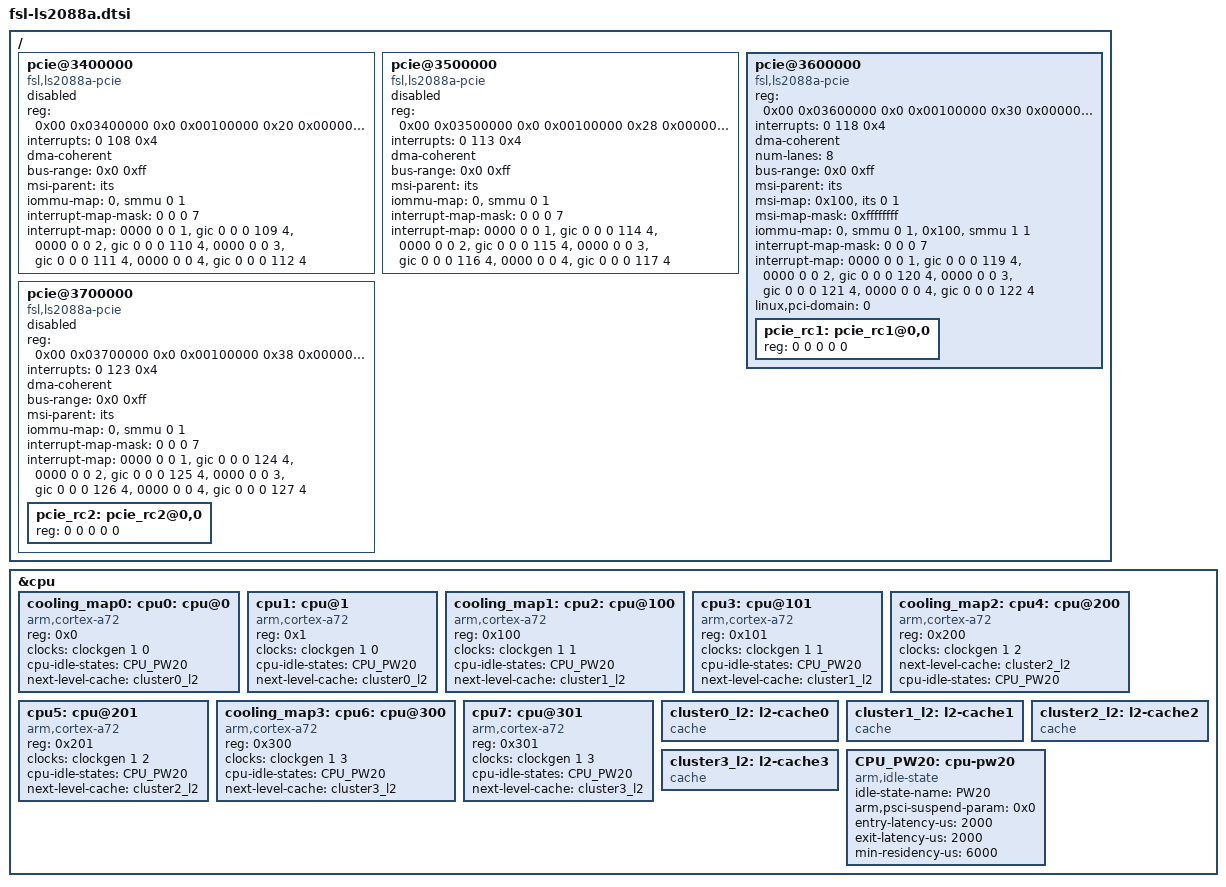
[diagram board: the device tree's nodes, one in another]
// SPDX-License-Identifier: (GPL-2.0+ OR MIT)
/*
 * Device Tree Include file for Freescale Layerscape-2088A family SoC.
 *
 * Copyright 2016 Freescale Semiconductor, Inc.
 * Copyright 2017-2018 NXP
 *
 * Abhimanyu Saini <abhimanyu.saini@nxp.com>
 *
 */

#include "fsl-ls208xa.dtsi"

&cpu {
	cooling_map0: cpu0: cpu@0 {
		device_type = "cpu";
		compatible = "arm,cortex-a72";
		reg = <0x0>;
		clocks = <&clockgen 1 0>;
		cpu-idle-states = <&CPU_PW20>;
		next-level-cache = <&cluster0_l2>;
		#cooling-cells = <2>;
	};

	cpu1: cpu@1 {
		device_type = "cpu";
		compatible = "arm,cortex-a72";
		reg = <0x1>;
		clocks = <&clockgen 1 0>;
		cpu-idle-states = <&CPU_PW20>;
		next-level-cache = <&cluster0_l2>;
		#cooling-cells = <2>;
	};

	cooling_map1: cpu2: cpu@100 {
		device_type = "cpu";
		compatible = "arm,cortex-a72";
		reg = <0x100>;
		clocks = <&clockgen 1 1>;
		cpu-idle-states = <&CPU_PW20>;
		next-level-cache = <&cluster1_l2>;
		#cooling-cells = <2>;
	};

	cpu3: cpu@101 {
		device_type = "cpu";
		compatible = "arm,cortex-a72";
		reg = <0x101>;
		clocks = <&clockgen 1 1>;
		cpu-idle-states = <&CPU_PW20>;
		next-level-cache = <&cluster1_l2>;
		#cooling-cells = <2>;
	};

	cooling_map2: cpu4: cpu@200 {
		device_type = "cpu";
		compatible = "arm,cortex-a72";
		reg = <0x200>;
		clocks = <&clockgen 1 2>;
		next-level-cache = <&cluster2_l2>;
		cpu-idle-states = <&CPU_PW20>;
		#cooling-cells = <2>;
	};

	cpu5: cpu@201 {
		device_type = "cpu";
		compatible = "arm,cortex-a72";
		reg = <0x201>;
		clocks = <&clockgen 1 2>;
		cpu-idle-states = <&CPU_PW20>;
		next-level-cache = <&cluster2_l2>;
		#cooling-cells = <2>;
	};

	cooling_map3: cpu6: cpu@300 {
		device_type = "cpu";
		compatible = "arm,cortex-a72";
		reg = <0x300>;
		clocks = <&clockgen 1 3>;
		cpu-idle-states = <&CPU_PW20>;
		next-level-cache = <&cluster3_l2>;
		#cooling-cells = <2>;
	};

	cpu7: cpu@301 {
		device_type = "cpu";
		compatible = "arm,cortex-a72";
		reg = <0x301>;
		clocks = <&clockgen 1 3>;
		cpu-idle-states = <&CPU_PW20>;
		next-level-cache = <&cluster3_l2>;
		#cooling-cells = <2>;
	};

	cluster0_l2: l2-cache0 {
		compatible = "cache";
	};

	cluster1_l2: l2-cache1 {
		compatible = "cache";
	};

	cluster2_l2: l2-cache2 {
		compatible = "cache";
	};

	cluster3_l2: l2-cache3 {
		compatible = "cache";
	};

	CPU_PW20: cpu-pw20 {
		compatible = "arm,idle-state";
		idle-state-name = "PW20";
		arm,psci-suspend-param = <0x0>;
		entry-latency-us = <2000>;
		exit-latency-us = <2000>;
		min-residency-us = <6000>;
	};
};

/ {
	pcie@3400000 {
		compatible = "fsl,ls2088a-pcie", "snps,dw-pcie";
		reg = <0x00 0x03400000 0x0 0x00100000   /* controller registers */
			0x20 0x00000000 0x0 0x00002000>; /* configuration space */

		ranges = <0x81000000 0x0 0x00000000 0x20 0x00010000 0x0 0x00010000
			0x82000000 0x0 0x40000000 0x20 0x40000000 0x0 0x40000000>;
		reg-names = "regs", "config";
		interrupts = <0 108 0x4>; /* aer interrupt */
		interrupt-names = "aer";
		#address-cells = <3>;
		#size-cells = <2>;
		device_type = "pci";
		dma-coherent;
		bus-range = <0x0 0xff>;
		msi-parent = <&its>;
		iommu-map = <0 &smmu 0 1>;	/* This is fixed-up by u-boot */
		#interrupt-cells = <1>;
		interrupt-map-mask = <0 0 0 7>;
		interrupt-map = <0000 0 0 1 &gic 0 0 0 109 4>,
				<0000 0 0 2 &gic 0 0 0 110 4>,
				<0000 0 0 3 &gic 0 0 0 111 4>,
				<0000 0 0 4 &gic 0 0 0 112 4>;
		status = "disabled";
	};

	pcie@3500000 {
		compatible = "fsl,ls2088a-pcie", "snps,dw-pcie";
		reg = <0x00 0x03500000 0x0 0x00100000   /* controller registers */
			0x28 0x00000000 0x0 0x00002000>; /* configuration space */

		ranges = <0x81000000 0x0 0x00000000 0x28 0x00010000 0x0 0x00010000
			0x82000000 0x0 0x40000000 0x28 0x40000000 0x0 0x40000000>;
		reg-names = "regs", "config";
		interrupts = <0 113 0x4>; /* aer interrupt */
		interrupt-names = "aer";
		#address-cells = <3>;
		#size-cells = <2>;
		device_type = "pci";
		dma-coherent;
		bus-range = <0x0 0xff>;
		msi-parent = <&its>;
		iommu-map = <0 &smmu 0 1>;	/* This is fixed-up by u-boot */
		#interrupt-cells = <1>;
		interrupt-map-mask = <0 0 0 7>;
		interrupt-map = <0000 0 0 1 &gic 0 0 0 114 4>,
				<0000 0 0 2 &gic 0 0 0 115 4>,
				<0000 0 0 3 &gic 0 0 0 116 4>,
				<0000 0 0 4 &gic 0 0 0 117 4>;
		status = "disabled";
	};

	pcie@3600000 {
		compatible = "fsl,ls2088a-pcie", "snps,dw-pcie";
		reg = <0x00 0x03600000 0x0 0x00100000   /* controller registers */
			0x30 0x00000000 0x0 0x00002000>; /* configuration space */

		ranges = <0x81000000 0x0 0x00000000 0x30 0x00010000 0x0 0x00010000
			0x82000000 0x0 0x40000000 0x30 0x40000000 0x0 0x40000000>;
		reg-names = "regs", "config";
		interrupts = <0 118 0x4>; /* aer interrupt */
		interrupt-names = "aer";
		#address-cells = <3>;
		#size-cells = <2>;
		device_type = "pci";
		dma-coherent;
		num-lanes = <8>;
		bus-range = <0x0 0xff>;
		msi-parent = <&its>;
		msi-map = <0x100 &its 0 1>;
		msi-map-mask = <0xffffffff>;
		iommu-map = <0 &smmu 0 1>,
		<0x100 &smmu 1 1>;
		#interrupt-cells = <1>;
		interrupt-map-mask = <0 0 0 7>;
		interrupt-map = <0000 0 0 1 &gic 0 0 0 119 4>,
				<0000 0 0 2 &gic 0 0 0 120 4>,
				<0000 0 0 3 &gic 0 0 0 121 4>,
				<0000 0 0 4 &gic 0 0 0 122 4>;
		linux,pci-domain = <0>;
		pcie_rc1: pcie_rc1@0,0 {
			reg = <0 0 0 0 0>;
		};
	};

	pcie@3700000 {
		compatible = "fsl,ls2088a-pcie", "snps,dw-pcie";
		reg = <0x00 0x03700000 0x0 0x00100000   /* controller registers */
			0x38 0x00000000 0x0 0x00002000>; /* configuration space */

		ranges = <0x81000000 0x0 0x00000000 0x38 0x00010000 0x0 0x00010000
			0x82000000 0x0 0x40000000 0x38 0x40000000 0x0 0x40000000>;
		reg-names = "regs", "config";
		interrupts = <0 123 0x4>; /* aer interrupt */
		interrupt-names = "aer";
		#address-cells = <3>;
		#size-cells = <2>;
		device_type = "pci";
		dma-coherent;
		bus-range = <0x0 0xff>;
		msi-parent = <&its>;
		iommu-map = <0 &smmu 0 1>;	/* This is fixed-up by u-boot */
		#interrupt-cells = <1>;
		interrupt-map-mask = <0 0 0 7>;
		interrupt-map = <0000 0 0 1 &gic 0 0 0 124 4>,
				<0000 0 0 2 &gic 0 0 0 125 4>,
				<0000 0 0 3 &gic 0 0 0 126 4>,
				<0000 0 0 4 &gic 0 0 0 127 4>;
		status = "disabled";

		pcie_rc2: pcie_rc2@0,0 {
			reg = <0 0 0 0 0>;
		};
	};
};
